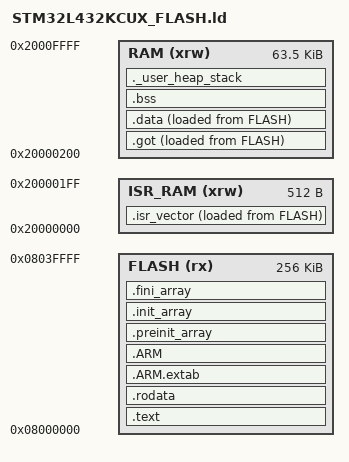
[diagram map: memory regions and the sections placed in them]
/**
 ******************************************************************************
 * @file      LinkerScript.ld
 * @author    Auto-generated by STM32CubeIDE
 *  Abstract    : Linker script for NUCLEO-L432KC Board embedding STM32L432KCUx Device from stm32l4 series
 *                      256Kbytes FLASH
 *                      64Kbytes RAM
 *
 *            Set heap size, stack size and stack location according
 *            to application requirements.
 *
 *            Set memory bank area and size if external memory is used
 ******************************************************************************
 * @attention
 *
 * <h2><center>&copy; Copyright (c) 2020 STMicroelectronics.
 * All rights reserved.</center></h2>
 *
 * This software component is licensed by ST under BSD 3-Clause license,
 * the "License"; You may not use this file except in compliance with the
 * License. You may obtain a copy of the License at:
 *                        opensource.org/licenses/BSD-3-Clause
 *
 ******************************************************************************
 */

/* Entry Point */
ENTRY(Reset_Handler)

/* Highest address of the user mode stack */
_estack = ORIGIN(RAM) + LENGTH(RAM);	/* end of "RAM" Ram type memory */

_Min_Heap_Size = 0x200 ;	/* required amount of heap  */
_Min_Stack_Size = 0x400 ;	/* required amount of stack */

FLASH_FULL_LEN = 256K ;
RAM_FULL_LEN = 64K ;
RAM_ISR_LEN = 512 ;

/* Memories definition */
MEMORY
{
  ISR_RAM  (xrw)  : ORIGIN = 0x20000000,  LENGTH = RAM_ISR_LEN
  RAM      (xrw)  : ORIGIN = ORIGIN(ISR_RAM) + LENGTH(ISR_RAM), LENGTH = RAM_FULL_LEN - LENGTH(ISR_RAM)
  FLASH     (rx)  : ORIGIN = 0x8000000,  LENGTH = FLASH_FULL_LEN
}

__flash_begin = ORIGIN(FLASH) ;
__flash_end = ORIGIN(FLASH) + LENGTH(FLASH) ;

/* Sections */
SECTIONS
{
  /* Interrupt vector table is forced to ISR_RAM, the first 512 bytes of RAM,   */
  /* must be loaded by ourselves from flash. In general ISR vector need to be   */
  /* located 512 byte aligned due to Vector Table Offset Register (VTOR)        */
  /* requirements if VTOR exist on the platform (it exists on Cortex-M4, but    */
  /* not in Cortex-M0 for example). In a system where we know we are relocating */
  /* the ISR table to RAM in any case, we dont need to care about where it is   */
  /* located in flash that much basically. This allows also some interesting    */
  /* tweaks later. Btw, reference manual says about ISR vector verbatim:        */
  /* The minimum alignment is 128 words                                         */

  .isr_vector :
  {
    . = ALIGN(4);
    KEEP(*(.isr_vector)) /* Startup code */
    . = ALIGN(4);
  } >ISR_RAM AT> FLASH
  __flash_vector_table_begin = LOADADDR(.isr_vector) ;
  __flash_vector_table_end = __flash_vector_table_begin + SIZEOF(.isr_vector) ;
  __ram_vector_table_begin = ADDR(.isr_vector) ;
  __ram_vector_table_end = __ram_vector_table_begin + SIZEOF(.isr_vector) ;


  /* Global Offset Table is relocated to regular RAM. No alignment constraints. */
  .got :
  {
    . = ALIGN(4);
    *(.got)
  } >RAM AT> FLASH
  __flash_global_offset_table_begin = LOADADDR(.got) ;
  __flash_global_offset_table_end = __flash_global_offset_table_begin + SIZEOF(.got) ;
  __ram_global_offset_table_begin = ADDR(.got) ;
  __ram_global_offset_table_end = __ram_global_offset_table_begin + SIZEOF(.got) ;


  /* The program code and other data into "FLASH" Rom type memory */
  .text :
  {
    . = ALIGN(4);
    *(.text)           /* .text sections (code) */
    *(.text*)          /* .text* sections (code) */
    *(.glue_7)         /* glue arm to thumb code */
    *(.glue_7t)        /* glue thumb to arm code */
    *(.eh_frame)

    KEEP (*(.init))
    KEEP (*(.fini))

    . = ALIGN(4);
    _etext = .;        /* define a global symbols at end of code */
  } >FLASH

  /* Constant data into "FLASH" Rom type memory */
  .rodata :
  {
    . = ALIGN(4);
    *(.rodata)         /* .rodata sections (constants, strings, etc.) */
    *(.rodata*)        /* .rodata* sections (constants, strings, etc.) */
    . = ALIGN(4);
  } >FLASH

  .ARM.extab   : {
    . = ALIGN(4);
    *(.ARM.extab* .gnu.linkonce.armextab.*)
    . = ALIGN(4);
  } >FLASH

  .ARM : {
    . = ALIGN(4);
    __exidx_start = .;
    *(.ARM.exidx*)
    __exidx_end = .;
    . = ALIGN(4);
  } >FLASH

  .preinit_array     :
  {
    . = ALIGN(4);
    PROVIDE_HIDDEN (__preinit_array_start = .);
    KEEP (*(.preinit_array*))
    PROVIDE_HIDDEN (__preinit_array_end = .);
    . = ALIGN(4);
  } >FLASH

  .init_array :
  {
    . = ALIGN(4);
    PROVIDE_HIDDEN (__init_array_start = .);
    KEEP (*(SORT(.init_array.*)))
    KEEP (*(.init_array*))
    PROVIDE_HIDDEN (__init_array_end = .);
    . = ALIGN(4);
  } >FLASH

  .fini_array :
  {
    . = ALIGN(4);
    PROVIDE_HIDDEN (__fini_array_start = .);
    KEEP (*(SORT(.fini_array.*)))
    KEEP (*(.fini_array*))
    PROVIDE_HIDDEN (__fini_array_end = .);
    . = ALIGN(4);
  } >FLASH

  /* Used by the startup to initialize data */
  _sidata = LOADADDR(.data);

  /* Initialized data sections into "RAM" Ram type memory */
  .data :
  {
    . = ALIGN(4);
    _sdata = .;        /* create a global symbol at data start */
    *(.data)           /* .data sections */
    *(.data*)          /* .data* sections */
    *(.RamFunc)        /* .RamFunc sections */
    *(.RamFunc*)       /* .RamFunc* sections */

    . = ALIGN(4);
    _edata = .;        /* define a global symbol at data end */

  } >RAM AT> FLASH

  /* Uninitialized data section into "RAM" Ram type memory */
  . = ALIGN(4);
  .bss :
  {
    /* This is used by the startup in order to initialize the .bss section */
    _sbss = .;         /* define a global symbol at bss start */
    __bss_start__ = _sbss;
    *(.bss)
    *(.bss*)
    *(COMMON)

    . = ALIGN(4);
    _ebss = .;         /* define a global symbol at bss end */
    __bss_end__ = _ebss;
  } >RAM

  /* User_heap_stack section, used to check that there is enough "RAM" Ram  type memory left */
  ._user_heap_stack :
  {
    . = ALIGN(8);
    PROVIDE ( end = . );
    PROVIDE ( _end = . );
    . = . + _Min_Heap_Size;
    . = . + _Min_Stack_Size;
    . = ALIGN(8);
  } >RAM

  /* Remove information from the compiler libraries */
  /DISCARD/ :
  {
    libc.a ( * )
    libm.a ( * )
    libgcc.a ( * )
  }

  .ARM.attributes 0 : { *(.ARM.attributes) }
}
